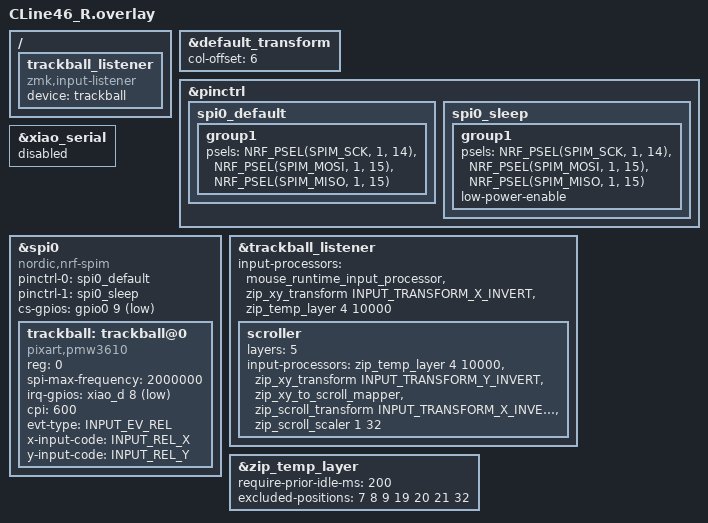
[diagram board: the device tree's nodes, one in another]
#include "CLine46.dtsi"
#include <zephyr/dt-bindings/input/input-event-codes.h>
#include <input/processors.dtsi>
#include <input/processors/runtime-input-processor.dtsi>
#include <behaviors/battery_history_request.dtsi>

&default_transform {
    col-offset = <6>;
};


/ {
    trackball_listener {
        status = "okay";
        compatible = "zmk,input-listener";
        device = <&trackball>;
    };
};

&pinctrl {
    spi0_default: spi0_default {
        group1 {
            psels = <NRF_PSEL(SPIM_SCK, 1, 14)>,
                <NRF_PSEL(SPIM_MOSI, 1, 15)>,
                <NRF_PSEL(SPIM_MISO, 1, 15)>;
        };
    };

    spi0_sleep: spi0_sleep {
        group1 {
            psels = <NRF_PSEL(SPIM_SCK, 1, 14)>,
                <NRF_PSEL(SPIM_MOSI, 1, 15)>,
                <NRF_PSEL(SPIM_MISO, 1, 15)>;
            low-power-enable;
        };
    };
};


&xiao_serial { status = "disabled"; };

&spi0 {
    status = "okay";
    compatible = "nordic,nrf-spim";
    pinctrl-0 = <&spi0_default>;
    pinctrl-1 = <&spi0_sleep>;
    pinctrl-names = "default", "sleep";
    cs-gpios = <&gpio0 9 GPIO_ACTIVE_LOW>;  //P0.09を指定(CS)

    trackball: trackball@0 {
        status = "okay";
        compatible = "pixart,pmw3610";
        reg = <0>;
        spi-max-frequency = <2000000>;
        irq-gpios = <&xiao_d 8 (GPIO_ACTIVE_LOW | GPIO_PULL_UP)>;
        cpi = <600>;
        //swap-xy;
        evt-type = <INPUT_EV_REL>;
        x-input-code = <INPUT_REL_X>;
        y-input-code = <INPUT_REL_Y>;
    };
};

// Overrides for the input listener node
&trackball_listener {
    status = "okay";
    input-processors =<&mouse_runtime_input_processor>,
        //<&zip_xy_transform INPUT_TRANSFORM_Y_INVERT>;       //Y軸反転
        //<&zip_xy_transform INPUT_TRANSFORM_XY_SWAP>,        //X軸とY軸の入れ替え
        <&zip_xy_transform INPUT_TRANSFORM_X_INVERT>,       //X軸反転
        <&zip_temp_layer 4 10000>;                          //オートマウスレイヤー: ボールを動かすとレイヤー4に入り、10秒動かさないと抜ける


    scroller {
        layers = <5>;
        input-processors =
            <&zip_temp_layer 4 10000>,                          //ボールでスクロールしている間も、レイヤー4の残り時間を10秒に戻す
            // <&zip_xy_transform INPUT_TRANSFORM_XY_SWAP>,        //X軸とY軸の入れ替え
            // <&zip_xy_transform INPUT_TRANSFORM_X_INVERT>,       //X軸反転
            <&zip_xy_transform INPUT_TRANSFORM_Y_INVERT>,       //Y軸反転
            <&zip_xy_to_scroll_mapper>,                         //スクロールモードに変更
            <&zip_scroll_transform INPUT_TRANSFORM_X_INVERT>,   //スクロールのX軸反転
            //<&zip_scroll_transform INPUT_TRANSFORM_Y_INVERT>,   //スクロールのY軸反転
            <&zip_scroll_scaler 1 32>;                          //スクロール量を1/32倍（Keyball の KEYBALL_SCROLL_DIV_DEFAULT 6 と同じ）
    };
};

// オートマウスレイヤー（レイヤー4）の動き方
&zip_temp_layer {
    // キーを打ってから 200ms はボールを動かしてもレイヤーに入らない
    require-prior-idle-ms = <200>;
    // 次の位置のキーを押してもレイヤーから抜けない。ここにないキーを押すとすぐに抜ける
    //   7: MB4  8: スクロール(I)  9: MB5  19: MB1  20: スクロール(K)  21: MB2
    //   32: ボールでスクロール(&mo 5)
    excluded-positions = <7 8 9 19 20 21 32>;
};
